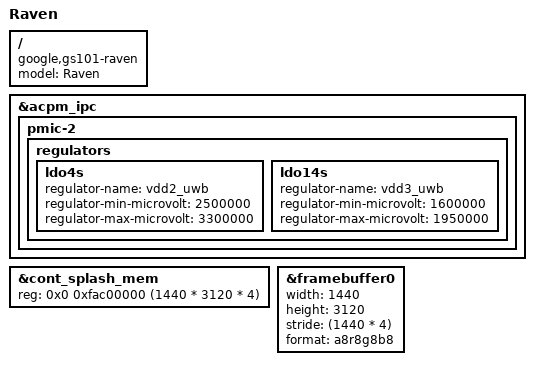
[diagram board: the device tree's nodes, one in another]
// SPDX-License-Identifier: GPL-2.0-only
/*
 * Raven Device Tree
 *
 * Copyright 2021-2023 Google LLC
 * Copyright 2023-2025 Linaro Ltd
 */

/dts-v1/;

#include "gs101-pixel-common.dtsi"

/ {
	model = "Raven";
	compatible = "google,gs101-raven", "google,gs101";
};

&acpm_ipc {
	pmic-2 {
		regulators {
			ldo4s {
				regulator-name = "vdd2_uwb";
				regulator-min-microvolt = <2500000>;
				regulator-max-microvolt = <3300000>;
			};

			ldo14s {
				regulator-name = "vdd3_uwb";
				regulator-min-microvolt = <1600000>;
				regulator-max-microvolt = <1950000>;
			};
		};
	};
};

&cont_splash_mem {
	reg = <0x0 0xfac00000 (1440 * 3120 * 4)>;
	status = "okay";
};

&framebuffer0 {
	width = <1440>;
	height = <3120>;
	stride = <(1440 * 4)>;
	format = "a8r8g8b8";
	status = "okay";
};
